# LAN9255ZMX020 register map
Vendor: Microchip
Registers are 32-bit, read-write, reset 0x0 unless marked. A register's access mark holds for its fields unless they carry their own. Addresses are absolute, and some are shared; only a register's first bit layout is shown; [hi:lo] are bit positions; {n}, {i} and the like mark numbered series; 'fields as' and 'values as' point back to an identical list.

## CCL
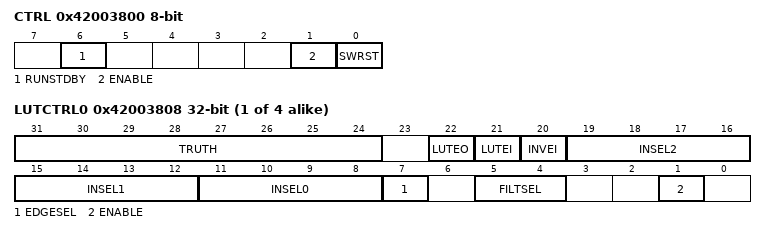
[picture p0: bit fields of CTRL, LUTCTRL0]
0x42003800 CTRL 8-bit
  [6] RUNSTDBY — Run in Standby
    0=DISABLE (Generic clock is not required in standby sleep mode); 1=ENABLE (Generic clock is required in standby sleep mode)
  [1] ENABLE
    0=DISABLE (The peripheral is disabled); 1=ENABLE (The peripheral is enabled)
  [0] SWRST — Software Reset
    0=DISABLE (The peripheral is not reset); 1=ENABLE (The peripheral is reset)
0x42003804 SEQCTRL0 8-bit
  [3:0] SEQSEL — Sequential Selection
    0=DISABLE (Sequential logic is disabled); 1=DFF (D flip flop); 2=JK (JK flip flop); 3=LATCH (D latch); 4=RS (RS latch)
0x42003805 SEQCTRL1 8-bit
  fields as SEQCTRL0
{0x42003808+4i} LUTCTRL{i} (i=0..3)
  [31:24] TRUTH — Truth Value
  [22] LUTEO — LUT Event Output Enable
    0=DISABLE (LUT event output is disabled); 1=ENABLE (LUT event output is enabled)
  [21] LUTEI — LUT Event Input Enable
    0=DISABLE (LUT incoming event is disabled); 1=ENABLE (LUT incoming event is enabled)
  [20] INVEI — Inverted Event Input Enable
    0=DISABLE (Incoming event is not inverted); 1=ENABLE (Incoming event is inverted)
  [19:16] INSEL2 — Input Selection 2
    0=MASK (Masked input); 1=FEEDBACK (Feedback input source); 2=LINK (Linked LUT input source); 3=EVENT (Event input source); 4=IO (I/O pin input source); 5=AC (AC input source); 6=TC (TC input source); 7=ALTTC (Alternate TC input source); 8=TCC (TCC input source); 9=SERCOM (SERCOM input source)
  [15:12] INSEL1 — Input Selection 1
    values as INSEL2
  [11:8] INSEL0 — Input Selection 0
    values as INSEL2
  [7] EDGESEL — Edge Selection
    0=DISABLE (Edge detector is disabled); 1=ENABLE (Edge detector is enabled)
  [5:4] FILTSEL — Filter Selection
    0=DISABLE (Filter disabled); 1=SYNCH (Synchronizer enabled); 2=FILTER (Filter enabled)
  [1] ENABLE — LUT Enable
    0=DISABLE (LUT block is disabled); 1=ENABLE (LUT block is enabled)

## DAC
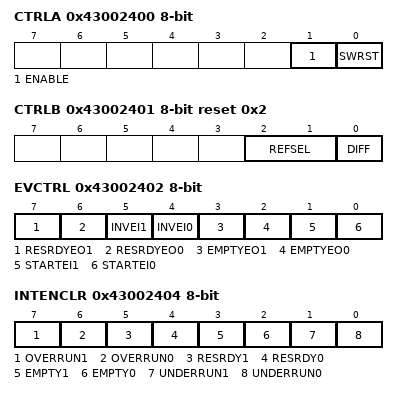
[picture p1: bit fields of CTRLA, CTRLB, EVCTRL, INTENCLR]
0x43002400 CTRLA 8-bit
  [1] ENABLE — Enable DAC Controller
  [0] SWRST — Software Reset
0x43002401 CTRLB 8-bit reset 0x2
  [2:1] REFSEL — Reference Selection for DAC0/1
    0=VREFPU (External reference unbuffered); 1=VDDANA (Analog supply); 2=VREFPB (External reference buffered); 3=INTREF (Internal bandgap reference)
  [0] DIFF — Differential mode enable
0x43002402 EVCTRL 8-bit
  [7] RESRDYEO1 — Result Ready Event Output 1
  [6] RESRDYEO0 — Result Ready Event Output 0
  [5] INVEI1 — Enable Invertion of DAC 1 input event
  [4] INVEI0 — Enable Invertion of DAC 0 input event
  [3] EMPTYEO1 — Data Buffer Empty Event Output DAC 1
  [2] EMPTYEO0 — Data Buffer Empty Event Output DAC 0
  [1] STARTEI1 — Start Conversion Event Input DAC 1
  [0] STARTEI0 — Start Conversion Event Input DAC 0
0x43002404 INTENCLR 8-bit
  [7] OVERRUN1 — Overrun 1 Interrupt Enable
  [6] OVERRUN0 — Overrun 0 Interrupt Enable
  [5] RESRDY1 — Result 1 Ready Interrupt Enable
  [4] RESRDY0 — Result 0 Ready Interrupt Enable
  [3] EMPTY1 — Data Buffer 1 Empty Interrupt Enable
  [2] EMPTY0 — Data Buffer 0 Empty Interrupt Enable
  [1] UNDERRUN1 — Underrun 1 Interrupt Enable
  [0] UNDERRUN0 — Underrun 0 Interrupt Enable
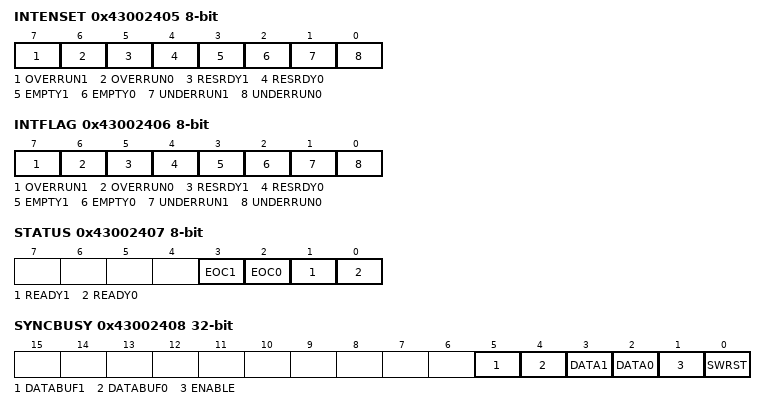
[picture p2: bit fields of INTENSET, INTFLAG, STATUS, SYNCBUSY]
0x43002405 INTENSET 8-bit
  fields as INTENCLR
0x43002406 INTFLAG 8-bit
  [7] OVERRUN1 — Result 1 Overrun
  [6] OVERRUN0 — Result 0 Overrun
  [5] RESRDY1 — Result 1 Ready
  [4] RESRDY0 — Result 0 Ready
  [3] EMPTY1 — Data Buffer 1 Empty
  [2] EMPTY0 — Data Buffer 0 Empty
  [1] UNDERRUN1 — Result 1 Underrun
  [0] UNDERRUN0 — Result 0 Underrun
0x43002407 STATUS 8-bit ro
  [3] EOC1 — DAC 1 End of Conversion
  [2] EOC0 — DAC 0 End of Conversion
  [1] READY1 — DAC 1 Startup Ready
  [0] READY0 — DAC 0 Startup Ready
0x43002408 SYNCBUSY ro
  [5] DATABUF1 — Data Buffer DAC 1
  [4] DATABUF0 — Data Buffer DAC 0
  [3] DATA1 — Data DAC 1
  [2] DATA0 — Data DAC 0
  [1] ENABLE — DAC Enable Status
  [0] SWRST — Software Reset
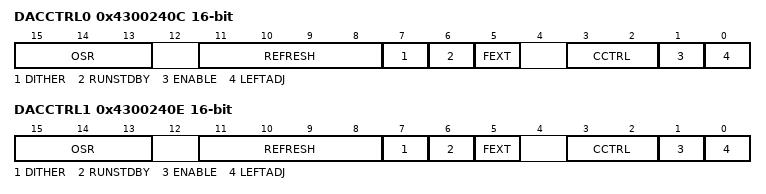
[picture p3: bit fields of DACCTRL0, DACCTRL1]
0x4300240C DACCTRL0 16-bit
  [15:13] OSR — Sampling Rate
    0=No Over Sampling; 1=2x Over Sampling Ratio; 2=4x Over Sampling Ratio; 3=8x Over Sampling Ratio; 4=16x Over Sampling Ratio; 5=32x Over Sampling Ratio
  [11:8] REFRESH — Refresh period
    0=Do not Refresh; 1=Refresh every 30 us; 2=Refresh every 60 us; 3=Refresh every 90 us; 4=Refresh every 120 us; 5=Refresh every 150 us; 6=Refresh every 180 us; 7=Refresh every 210 us; 8=Refresh every 240 us; 9=Refresh every 270 us; 10=Refresh every 300 us; 11=Refresh every 330 us; 12=Refresh every 360 us; 13=Refresh every 390 us; 14=Refresh every 420 us; 15=Refresh every 450 us
  [7] DITHER — Dithering Mode
  [6] RUNSTDBY — Run in Standby
  [5] FEXT — Standalone Filter
  [3:2] CCTRL — Current Control
    0=CC100K (100kSPS); 1=CC1M (500kSPS); 2=CC12M (1MSPS)
  [1] ENABLE — Enable DAC0
  [0] LEFTADJ — Left Adjusted Data
0x4300240E DACCTRL1 16-bit
  fields as DACCTRL0
0x43002410 DATA0 16-bit wo
  [15:0] DATA — DAC0 Data
0x43002412 DATA1 16-bit wo
  [15:0] DATA — DAC0 Data
0x43002414 DATABUF0 16-bit wo
  [15:0] DATABUF — DAC0 Data Buffer
0x43002416 DATABUF1 16-bit wo
  [15:0] DATABUF — DAC0 Data Buffer
0x43002418 DBGCTRL 8-bit
  [0] DBGRUN — Debug Run
0x4300241C RESULT0 16-bit ro
  [15:0] RESULT — Filter Result
0x4300241E RESULT1 16-bit ro
  [15:0] RESULT — Filter Result

## PCC
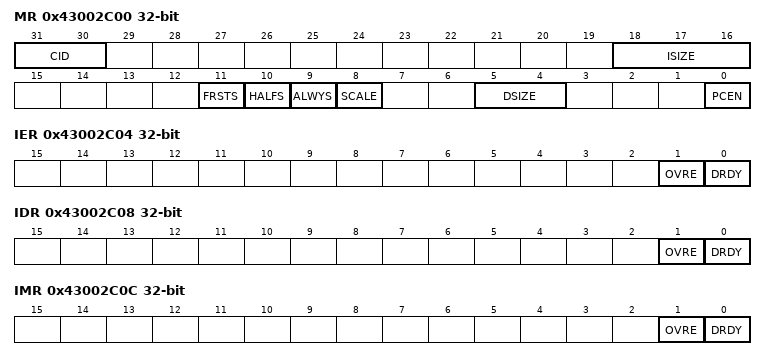
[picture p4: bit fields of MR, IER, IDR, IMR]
0x43002C00 MR
  [31:30] CID — Clear If Disabled
  [18:16] ISIZE — Input Data Size
  [11] FRSTS — First sample
  [10] HALFS — Half Sampling
  [9] ALWYS — Always Sampling
  [8] SCALE — Scale data
  [5:4] DSIZE — Data size
  [0] PCEN — Parallel Capture Enable
0x43002C04 IER wo
  [1] OVRE — Overrun Error Interrupt Enable
  [0] DRDY — Data Ready Interrupt Enable
0x43002C08 IDR wo
  [1] OVRE — Overrun Error Interrupt Disable
  [0] DRDY — Data Ready Interrupt Disable
0x43002C0C IMR ro
  [1] OVRE — Overrun Error Interrupt Mask
  [0] DRDY — Data Ready Interrupt Mask
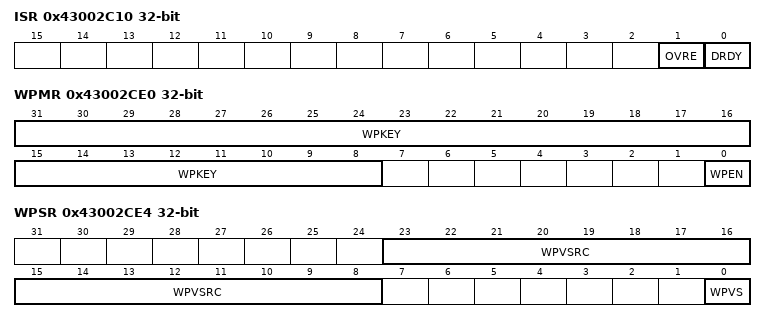
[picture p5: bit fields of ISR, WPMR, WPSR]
0x43002C10 ISR ro
  [1] OVRE — Overrun Error Interrupt Status
  [0] DRDY — Data Ready Interrupt Status
0x43002C14 RHR ro
  [31:0] RDATA — Reception Data
0x43002CE0 WPMR
  [31:8] WPKEY — Write Protection Key
  [0] WPEN — Write Protection Enable
0x43002CE4 WPSR ro
  [23:8] WPVSRC — Write Protection Violation Status
  [0] WPVS — Write Protection Violation Source

## CONFIG — Configuration words, addresses in PhysicalSpace
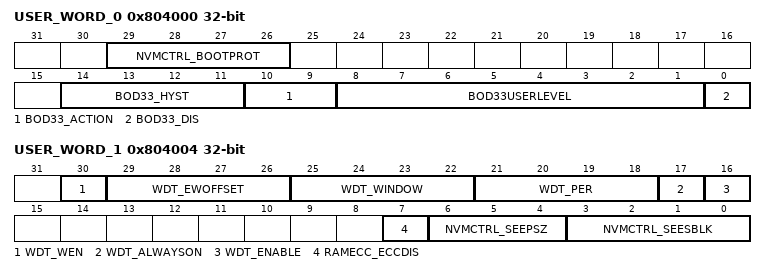
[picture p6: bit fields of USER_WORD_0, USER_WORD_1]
0x804000 USER_WORD_0
  [29:26] NVMCTRL_BOOTPROT — Bootloader Size
    15=0 kbytes; 14=8 kbytes; 13=16 kbytes; 12=24 kbytes; 11=32 kbytes; 10=40 kbytes; 9=48 kbytes; 8=56 kbytes; 7=64 kbytes; 6=72 kbytes; 5=80 kbytes; 4=88 kbytes; 3=96 kbytes; 2=104 kbytes; 1=112 kbytes; 0=120 kbytes
  [14:11] BOD33_HYST — BOD33 Hysteresis
  [10:9] BOD33_ACTION
    0=NONE (No action); 1=RESET (The BOD33 generates a reset); 2=INT (The BOD33 generates an interrupt); 3=BKUP (The BOD33 puts the device in backup sleep mode)
  [8:1] BOD33USERLEVEL
  [0] BOD33_DIS — BOD33 Disable
    1=SET; 0=CLEAR
0x804004 USER_WORD_1
  [30] WDT_WEN — WDT Window Mode Enable
    1=SET; 0=CLEAR
  [29:26] WDT_EWOFFSET — WDT Early Warning Offset
    0=CYC8 (8 clock cycles); 1=CYC16 (16 clock cycles); 2=CYC32 (32 clock cycles); 3=CYC64 (64 clock cycles); 4=CYC128 (128 clock cycles); 5=CYC256 (256 clock cycles); 6=CYC512 (512 clock cycles); 7=CYC1024 (1024 clock cycles); 8=CYC2048 (2048 clock cycles); 9=CYC4096 (4096 clock cycles); 10=CYC8192 (8192 clock cycles); 11=CYC16384 (16384 clock cycles)
  [25:22] WDT_WINDOW
    values as WDT_EWOFFSET
  [21:18] WDT_PER — WDT Period
    values as WDT_EWOFFSET
  [17] WDT_ALWAYSON
    1=SET; 0=CLEAR
  [16] WDT_ENABLE
    1=SET; 0=CLEAR
  [7] RAMECC_ECCDIS — RAM ECC Disable fuse
    1=SET; 0=CLEAR
  [6:4] NVMCTRL_SEEPSZ — Size Of SmartEEPROM Page
  [3:0] NVMCTRL_SEESBLK — Number Of Physical NVM Blocks Composing a SmartEEPROM Sector
0x804008 USER_WORD_2
  [31:0] NVMCTRL_REGION_LOCKS — NVM Region Locks
